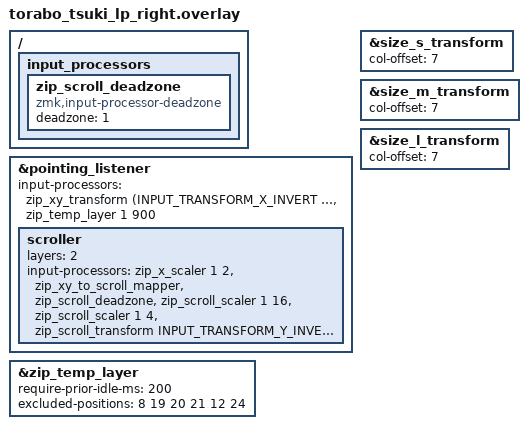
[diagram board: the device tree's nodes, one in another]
#include "torabo_tsuki_lp.dtsi"
#include <input/processors.dtsi>
#include <dt-bindings/zmk/input_transform.h>

/ {
    input_processors {
        /omit-if-no-ref/ zip_scroll_deadzone: zip_scroll_deadzone {
            compatible = "zmk,input-processor-deadzone";
            #input-processor-cells = <0>;
            deadzone = <1>;
        };
    };
};

&pointing_listener {
    input-processors =
        <&zip_xy_transform (INPUT_TRANSFORM_X_INVERT | INPUT_TRANSFORM_Y_INVERT)>,
        <&zip_temp_layer 1 900>;

    scroller {
        layers = <2>;
        input-processors =
            <&zip_x_scaler 1 2>,
            <&zip_xy_to_scroll_mapper>,
            <&zip_scroll_deadzone>,
            <&zip_scroll_scaler 1 16>,
            <&zip_scroll_scaler 1 4>,
            <&zip_scroll_transform INPUT_TRANSFORM_Y_INVERT>;
    };
};

&zip_temp_layer {
    require-prior-idle-ms = <200>;
    excluded-positions = <
        8  // I
        19 // J
        20 // K
        21 // L
        12 // Control
        24 // Shift
    >;
};

&size_s_transform {
    col-offset = <7>;
};

&size_m_transform {
    col-offset = <7>;
};

&size_l_transform {
    col-offset = <7>;
};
